# DSS_EDP0_V2A_CORE_VP_REGS_APB register map
Vendor: Texas Instruments
Registers are 32-bit, access not given, reset 0x0 unless marked. A register's access mark holds for its fields unless they carry their own. Offsets are as the file gives them; [hi:lo] are bit positions; {n}, {i} and the like mark numbered series.

## DSS_EDP0_V2A_CORE_VP_REGS_APB (part 2 of 4)
0x40 V2A__CORE_VP__REGS_APB_SW_CLK_H_p reset 0x64 — Core Clock frequency
  [7:0] SW_CLOCK_VAL_H rw — Clock frequency in decimal values. Should be loaded by API to the value that reflects the frequency of clock provided to core clock input.
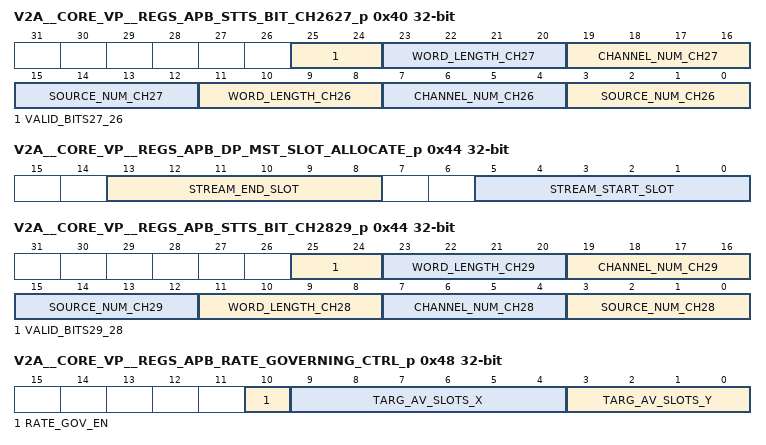
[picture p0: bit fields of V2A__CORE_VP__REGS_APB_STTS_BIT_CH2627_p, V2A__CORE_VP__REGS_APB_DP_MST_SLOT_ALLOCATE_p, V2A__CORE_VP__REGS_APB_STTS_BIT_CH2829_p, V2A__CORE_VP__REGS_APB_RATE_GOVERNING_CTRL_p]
0x40 V2A__CORE_VP__REGS_APB_STTS_BIT_CH2627_p — Channels 26,27 configuration
  [25:24] VALID_BITS27_26 rw — Valid Bits for channel 27 and 26 if force is enabled
  [23:20] WORD_LENGTH_CH27 rw — Channel 27 word length.
  [19:16] CHANNEL_NUM_CH27 rw — Channel 27 channel number.
  [15:12] SOURCE_NUM_CH27 rw — Channel 27 Source number.
  [11:8] WORD_LENGTH_CH26 rw — Channel 26 word length.
  [7:4] CHANNEL_NUM_CH26 rw — Channel 26 channel number.
  [3:0] SOURCE_NUM_CH26 rw — Channel 26 Source number.
0x44 V2A__CORE_VP__REGS_APB_SW_EVENTS0_p — Bits [7:0] of the software events status vector. This register is used to report internal events that have been detected by the firmware to the host processor. Register is written by the internal uCPU. It is cleared upon read by the Host processor. Reported events can be source of interrupt reported in APB_INT_STATUS[1] register if this interrupt is enabled. Detailed description of the currently supported events can be found in Cadence HD Display TX Controller Programming Interface document.
  [7:0] SW_EVENTS7_0 ro — Each bit represents a separate event reported by the internal uCPU. If bit is set to 1 event is reported. All events are cleared upon read. Detailed description in Cadence HD Display TX Controller Programming Interface document.
0x44 V2A__CORE_VP__REGS_APB_DP_MST_SLOT_ALLOCATE_p — Stream slots allocation in MST mode. This register defines slots in the MTP assigned to a given stream. All slots between start and and are assigned to the stream. Assignement of noncontiguous slots to a single stream is not supported.
  [13:8] STREAM_END_SLOT rw — Stream end slot. This value determines last slot in MTP assigned to a given stream. Allowed values are stream_start_slot-63.
  [5:0] STREAM_START_SLOT rw — Stream start slot. This value determines first slot in MTP assigned to a given stream. Allowed values are 1-63.
0x44 V2A__CORE_VP__REGS_APB_STTS_BIT_CH2829_p — Channels 28,29 configuration
  [25:24] VALID_BITS29_28 rw — Valid Bits for channel 29 and 28 if force is enabled
  [23:20] WORD_LENGTH_CH29 rw — Channel 29 word length.
  [19:16] CHANNEL_NUM_CH29 rw — Channel 29 channel number.
  [15:12] SOURCE_NUM_CH29 rw — Channel 29 Source number.
  [11:8] WORD_LENGTH_CH28 rw — Channel 28 word length.
  [7:4] CHANNEL_NUM_CH28 rw — Channel 28 channel number.
  [3:0] SOURCE_NUM_CH28 rw — Channel 28 Source number.
{0x44+4i} V2A__CORE_VP__REGS_APB_SW_EVENTS{i}_p (i=1..3) — SW Event {i} register
  [7:0] SW_EVENTS{8i+7}_{8i} ro — Each bit represents a separate event reported by the internal uCPU. If bit is set to 1 event is reported. All events are cleared upon read. Detailed description in Cadence HD Display TX Controller Programming Interface document.
0x48 V2A__CORE_VP__REGS_APB_RATE_GOVERNING_CTRL_p — Control rate governing for stream in MST mode.
  [10] RATE_GOV_EN rw — Enable rate governing. When set to 0, this stream will only output VCPF
  [9:4] TARG_AV_SLOTS_X rw — Target average number of slots per MTP configuration
  [3:0] TARG_AV_SLOTS_Y rw — Target average number of slots per MTP configuration. Fractional component
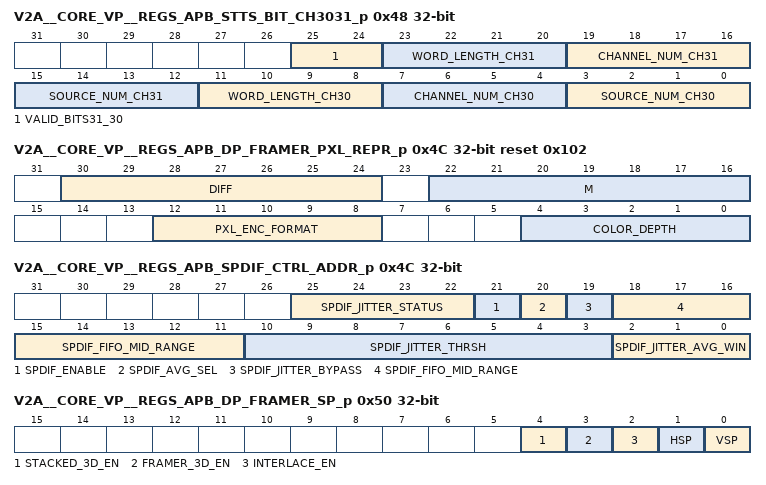
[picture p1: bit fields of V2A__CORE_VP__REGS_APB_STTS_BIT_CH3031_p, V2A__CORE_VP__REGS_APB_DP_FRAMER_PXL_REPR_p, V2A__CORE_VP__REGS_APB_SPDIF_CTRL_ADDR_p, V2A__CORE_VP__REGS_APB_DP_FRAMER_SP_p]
0x48 V2A__CORE_VP__REGS_APB_STTS_BIT_CH3031_p — Channels 30,31 configuration
  [25:24] VALID_BITS31_30 rw — Valid Bits for channel 31 and 30 if force is enabled
  [23:20] WORD_LENGTH_CH31 rw — Channel 31 word length.
  [19:16] CHANNEL_NUM_CH31 rw — Channel 31 channel number.
  [15:12] SOURCE_NUM_CH31 rw — Channel 31 Source number.
  [11:8] WORD_LENGTH_CH30 rw — Channel 30 word length.
  [7:4] CHANNEL_NUM_CH30 rw — Channel 30 channel number.
  [3:0] SOURCE_NUM_CH30 rw — Channel 30 Source number.
0x4C V2A__CORE_VP__REGS_APB_DP_FRAMER_PXL_REPR_p reset 0x102 — Video pixel format configuration. This register must be programmed prior enabling video and must not be changed while video is being transmitted.
  [30:24] DIFF rw — Difference between Denominator and Numerator of the ratio that describes valid symbols distribution. Example: If TU_VALID*=12.34 then DIFF=100-34=66. TU_VALID calculated according to DisplayPort specification. This setting apply only when compressed [DSC] stream is being transmitted.
  [22:16] M rw — Numerator of the ratio that describes valid symbols distribution. Example: If TU_VALID=12.34 then M=34. TU_VALID calculated according to DisplayPort specification. This setting apply only when compressed [DSC] stream is being transmitted.
  [12:8] PXL_ENC_FORMAT rw — Pixel encoding format: 1h - RGB 2h - YCbCr 4:4:4 4h - YCbCr 4:2:2 8h - Y CbCr 4:2:0 10h - Y-only All other values - RESERVED
  [4:0] COLOR_DEPTH rw — Color depth: 1h - 6 bpc, 2h - 8 bpc, 4h - 10 bpc, 8h - 12 bpc, 10h - 16 bpc, All other values - RESERVED
0x4C V2A__CORE_VP__REGS_APB_SPDIF_CTRL_ADDR_p — SPDIF control
  [25:22] SPDIF_JITTER_STATUS ro
  [21] SPDIF_ENABLE rw
  [20] SPDIF_AVG_SEL rw — SPDIF average Select
  [19] SPDIF_JITTER_BYPASS rw
  [18:11] SPDIF_FIFO_MID_RANGE rw
  [10:3] SPDIF_JITTER_THRSH rw — SPDIF Jitter threshold
  [2:0] SPDIF_JITTER_AVG_WIN rw — Spdif Jitter AVG Window
0x50 V2A__CORE_VP__REGS_APB_DP_FRAMER_SP_p — Synchronization signals polarity and 3D control. This register must be programmed prior enabling video and must not be changed while video is being transmitted.
  [4] STACKED_3D_EN rw — Unused. Kept RW for software backward compatibility.
  [3] FRAMER_3D_EN rw — 3D video enable, active high. This bit must be set when 3D Field Sequencial Stereo Format is enabled. Other 3D formats do not require setting this bit.
  [2] INTERLACE_EN rw — Interlaced video enable. Active high.
  [1] HSP rw — Video interface HSYNC polarity: 0 - active high, 1 - active low
  [0] VSP rw — Video interface VSYNC polarity: 0 - active high, 1 - active low
0x50 V2A__CORE_VP__REGS_APB_SPDIF_CH1_CS_3100_ADDR_p ro — SPDIF channel 1 status [31:00]
  [31:0] SPDIF_CH1_ST_STTS_BITS3100 — SPDIF Channel 1 Status bits[31:0]
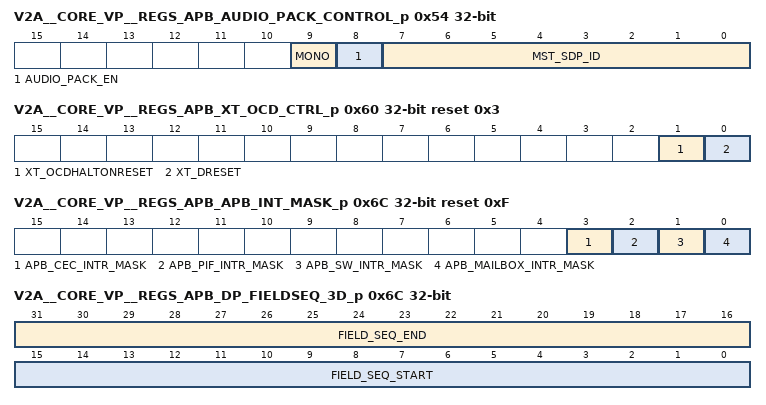
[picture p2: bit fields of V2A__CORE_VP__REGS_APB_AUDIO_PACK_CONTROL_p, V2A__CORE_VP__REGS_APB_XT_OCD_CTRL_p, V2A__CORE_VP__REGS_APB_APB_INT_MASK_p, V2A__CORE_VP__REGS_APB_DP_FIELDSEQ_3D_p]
0x54 V2A__CORE_VP__REGS_APB_AUDIO_PACK_CONTROL_p — Audio packet configuration.
  [9] MONO rw — In case of 2-channel layout and one lane configuration SW decides whether it is a stereo or mono transfer. Relevant for SDP HB3[2:0] - ChannelCount field
  [8] AUDIO_PACK_EN rw — Enables the Audio_Pack module, active high
  [7:0] MST_SDP_ID rw — Secondary-Data Packet ID. This field is transmitted in HB0 of the Audio SDP [Audio_TimeStamp and Audio_Stream].
0x54 V2A__CORE_VP__REGS_APB_SPDIF_CH1_CS_6332_ADDR_p ro — SPDIF channel 1 status [63:32]
  [31:0] SPDIF_CH1_ST_STTS_BITS6332 — SPDIF Channel 1 Status bits[63:32]
0x58 V2A__CORE_VP__REGS_APB_SPDIF_CH1_CS_9564_ADDR_p ro — SPDIF channel 1 status [95:64]
  [31:0] SPDIF_CH1_ST_STTS_BITS9564 — SPDIF Channel 1 Status bits[95:64]
0x5C V2A__CORE_VP__REGS_APB_SPDIF_CH1_CS_12796_ADDR_p ro — SPDIF channel 1 status [127:96]
  [31:0] SPDIF_CH1_ST_STTS_BITS12796 — SPDIF Channel 1 Status bits[127:96]
0x60 V2A__CORE_VP__REGS_APB_XT_OCD_CTRL_p reset 0x3 — Internal CPU - On Chip Debug (OCD) Ctrl Register
  [1] XT_OCDHALTONRESET rw — Internal CPU - Halt On Reget configuration register
  [0] XT_DRESET rw — Internal CPU - Dreset control register
0x60 V2A__CORE_VP__REGS_APB_SPDIF_CH1_CS_159128_ADDR_p ro — SPDIF channel 1 status [159:128]
  [31:0] SPDIF_CH1_ST_STTS_BITS159128 — SPDIF Channel 1 Status bits[159:128]
0x64 V2A__CORE_VP__REGS_APB_XT_OCD_CTRL_RO_p — Internal CPU - OCD R0 mode configuration
  [0] XT_XOCDMODE ro — Internal CPU - OCD mode configuration
0x64 V2A__CORE_VP__REGS_APB_LINE_THRESH_p reset 0x20 — Video FIFO latency threshold
  [5:0] CFG_ACTIVE_LINE_TRESH rw — Video Fifo Latency threshold. Defines the number of FIFO rows before reading starts. This setting depends on the transmitted video format and link rate.
0x64 V2A__CORE_VP__REGS_APB_SPDIF_CH1_CS_191160_ADDR_p ro — SPDIF channel 1 status [191:160]
  [31:0] SPDIF_CH1_ST_STTS_BITS191160 — SPDIF Channel 1 Status bits[191:160]
0x68 V2A__CORE_VP__REGS_APB_DP_VB_ID_p reset 0x9 — Vertical blanking ID
  [7:0] VB_ID rw — VB-ID as described in the DisplayPort specification. Bits that are timing dependent [VerticalBlanking_Flag, FieldID_Flag, HDCP SYNC DETECT, Compressed Stream_Flag] are overriden by hardware thus actual value written to the register is ignored.
0x68 V2A__CORE_VP__REGS_APB_SPDIF_CH2_CS_3100_ADDR_p ro — SPDIF channel 2 status [31:00]
  [31:0] SPDIF_CH2_ST_STTS_BITS3100 — SPDIF Channel 2 Status bits[31:0]
0x6C V2A__CORE_VP__REGS_APB_APB_INT_MASK_p reset 0xF — APB Interrupt Mask Register
  [3] APB_CEC_INTR_MASK rw — Reserved field. 0x0 when read. Writes ignored.
  [2] APB_PIF_INTR_MASK rw — PIF module Interrupt mask 0x0-interrupt enabled 0x1-interrupt disabled
  [1] APB_SW_INTR_MASK rw — SW Event Interrupt mask 0x0-interrupt enabled 0x1-interrupt disabled
  [0] APB_MAILBOX_INTR_MASK rw — Mailbox Interrupt mask 0x0-interrupt enabled 0x1-interrupt disabled
0x6C V2A__CORE_VP__REGS_APB_DP_FIELDSEQ_3D_p rw — Supporting configuration to switch from top/bottom on the input to field sequential on the output
  [31:16] FIELD_SEQ_END — Number of line in the frame where the Vblank part in the field sequential format ends
  [15:0] FIELD_SEQ_START — Number of line in the frame where the Vblank part in the field sequential format starts
0x6C V2A__CORE_VP__REGS_APB_SPDIF_CH2_CS_6332_ADDR_p ro — SPDIF channel 2 status [63:32]
  [31:0] SPDIF_CH2_ST_STTS_BITS6332 — SPDIF Channel 2 Status bits[63:32]
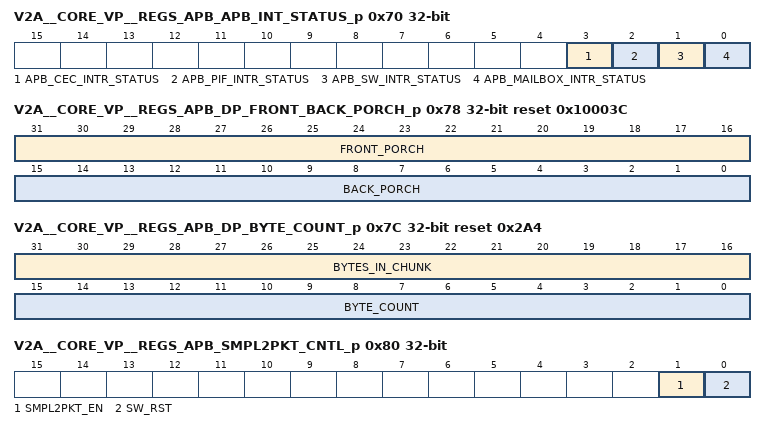
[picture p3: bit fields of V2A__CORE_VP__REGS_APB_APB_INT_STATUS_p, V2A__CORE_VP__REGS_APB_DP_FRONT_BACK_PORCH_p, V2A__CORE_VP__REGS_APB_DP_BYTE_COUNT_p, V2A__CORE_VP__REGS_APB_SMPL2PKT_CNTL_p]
0x70 V2A__CORE_VP__REGS_APB_APB_INT_STATUS_p — APB interrupt status register
  [3] APB_CEC_INTR_STATUS ro — Reserved.
  [2] APB_PIF_INTR_STATUS ro — PIF module Interrupt status. Active HIGH. If this bit is set further status should be read from SOURCE_PIF_INTERRUPT_SOURCE register. This bit is cleared automatically on read from SOURCE_PIF_INTERRUPT_SOURCE register.
  [1] APB_SW_INTR_STATUS ro — SW Events Interrupt status. Active HIGH. If this bit is set further status should be read from SW_EVENTSn registers. This bit is cleared automatically on read from SW_EVENTSn registers if there are no more events.
  [0] APB_MAILBOX_INTR_STATUS ro — Mailbox Interrupt status. Active HIGH. If this bit is set further status should be read from MAILBOX_INT_STATUS register. This bit is cleared automatically on read from MAILBOX_INT_STATUS register.
0x70 V2A__CORE_VP__REGS_APB_SPDIF_CH2_CS_9564_ADDR_p ro — SPDIF channel 2 status [95:64]
  [31:0] SPDIF_CH2_ST_STTS_BITS9564 — SPDIF Channel 2 Status bits[95:64]
0x74 V2A__CORE_VP__REGS_APB_SPDIF_CH2_CS_12796_ADDR_p ro — SPDIF channel 2 status [127:96]
  [31:0] SPDIF_CH2_ST_STTS_BITS12796 — SPDIF Channel 2 Status bits[127:96]
0x78 V2A__CORE_VP__REGS_APB_DP_FRONT_BACK_PORCH_p rw reset 0x10003C — Front and Back Porch configuration register. In case of compressed stream transmission (DSC) and split panel mode values in this register must be divided by 2 since VIF interface operates at pixel clock divided by 2. This will ensure the same timing compared to uncompressed stream and.
  [31:16] FRONT_PORCH — Value of the front porch
  [15:0] BACK_PORCH — Value of the back porch
0x78 V2A__CORE_VP__REGS_APB_SPDIF_CH2_CS_159128_ADDR_p ro — SPDIF channel 2 status [159:128]
  [31:0] SPDIF_CH2_ST_STTS_BITS159128 — SPDIF Channel 2 Status bits[159:128]
0x7C V2A__CORE_VP__REGS_APB_DP_BYTE_COUNT_p rw reset 0x2A4 — Number of bytes per lane/chunk parameters
  [31:16] BYTES_IN_CHUNK — Number of bytes in chunk per lane, including additional EOC symbol.
  [15:0] BYTE_COUNT — Total number of bytes in a line in case of non-DSC video. When DSC is enabled should be total number of bytes in a line *per lane*, including the additional EOC symbol[s].
0x7C V2A__CORE_VP__REGS_APB_SPDIF_CH2_CS_191160_ADDR_p ro — SPDIF channel 2 status [191:160]
  [31:0] SPDIF_CH2_ST_STTS_BITS191160 — SPDIF Channel 2 Status bits[191:160]
0x80 V2A__CORE_VP__REGS_APB_SMPL2PKT_CNTL_p — Sample 2 Packets Control Register
  [1] SMPL2PKT_EN rw — When high Sample to Packets Block starts.
  [0] SW_RST rw — Software reset. Active high.
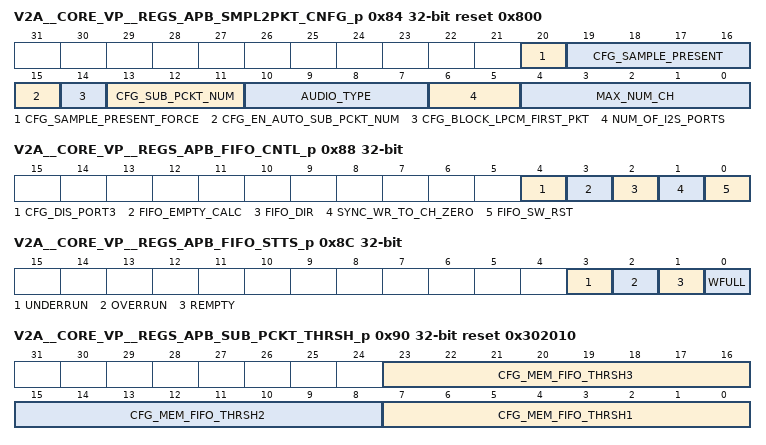
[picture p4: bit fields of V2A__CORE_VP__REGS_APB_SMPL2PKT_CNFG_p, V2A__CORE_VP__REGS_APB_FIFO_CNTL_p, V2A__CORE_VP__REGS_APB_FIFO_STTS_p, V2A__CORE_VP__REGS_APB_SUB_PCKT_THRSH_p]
0x84 V2A__CORE_VP__REGS_APB_SMPL2PKT_CNFG_p reset 0x800 — Sample 2 Packets Config Register
  [20] CFG_SAMPLE_PRESENT_FORCE rw — Force sample present bits
  [19:16] CFG_SAMPLE_PRESENT rw — Sample present bits if force them is active
  [15] CFG_EN_AUTO_SUB_PCKT_NUM rw — Enable automatics sub packet number. When enabled number of sub-packts will be set according to MEM FIFO number of samples.
  [14] CFG_BLOCK_LPCM_FIRST_PKT rw — 0 - All packets behave the same. 1- First lpcm audio packet is sent with 1 - SP.
  [13:11] CFG_SUB_PCKT_NUM rw — Number of sub-packets in HDMI audio 2-ch packet. 00: 1-SP 01: 2-SP 10: 3-SP 11: 4-SP. 100-111: NA.
  [10:7] AUDIO_TYPE rw — Audio Type setting. Packet is structured according to audio type.
  [6:5] NUM_OF_I2S_PORTS rw — Number ofactive I2S ports. 00- 1 port 01-2 ports 11- 4 ports 11 -NA.
  [4:0] MAX_NUM_CH rw — Number of channels to decode. 0: 1 channel 31: 32 channels
0x88 V2A__CORE_VP__REGS_APB_FIFO_CNTL_p — FIFO control register
  [4] CFG_DIS_PORT3 rw — 0 - Normal Operation. 1 - I2S port 3 is disabled [user should ignore its outputs]. This allows for 24-ch, 12-ch, 6-ch transfer.
  [3] FIFO_EMPTY_CALC rw — 0 - Empty is a function of read address. 1 - Empty is a function of BASE read address.
  [2] FIFO_DIR rw — 0 - smpl2pkt [inc_step=number of I2S ports] 1 - pkt2smpl [inc_step=num_ch_per_port]
  [1] SYNC_WR_TO_CH_ZERO rw — When high the last channel index synchronizes the write addresses [to the next channel group]
  [0] FIFO_SW_RST rw — Resets Fifo's write and read pointers. When FIFO configuration bits change this signal should be high [due to synchronization issues].
0x8C V2A__CORE_VP__REGS_APB_FIFO_STTS_p — FIFO Status register
  [3] UNDERRUN ro — Indicates a FIFO underrun error has occured - FIFO read when it was empty. For debug purposes, not synchronized.
  [2] OVERRUN ro — Indicates a FIFO overrun error has occured - FIFO written to when it was full. For debug purposes, not synchronized.
  [1] REMPTY ro — Indicates FIFO Empty. For debug purposes, not synchronized.
  [0] WFULL ro — Indicates FIFO Full. For debug purposes, not synchronized.
0x90 V2A__CORE_VP__REGS_APB_SUB_PCKT_THRSH_p reset 0x302010 — SUB Packet Threshold register
  [23:16] CFG_MEM_FIFO_THRSH3 rw — If number of samples in MEM FIFO is below Threshold 3: Each Packet will contain only 3 subpacket.
  [15:8] CFG_MEM_FIFO_THRSH2 rw — If number of samples in MEM FIFO is below Threshold2: Each Packet will contain only 2 subpacket.
  [7:0] CFG_MEM_FIFO_THRSH1 rw — If number of samples in MEM FIFO is below Threshold 1: Each Packet will contain only 1 subpacket.
0xA0 V2A__CORE_VP__REGS_APB_CDNS_DID_p ro reset 0x8546 — Number identifying the IP. Corresponds to Cadence IP Part Number.
  [31:0] IPVER — 0x8546 - DisplayPort 1.4/EmbeddedDisplayPort 1.4 Tx Combo Controller
0xA4 V2A__CORE_VP__REGS_APB_CDNS_RID0_p reset 0x2000 — Number identifying IP version.
  [15:0] IP_VERSION ro — IP version: r[15:4]v[3:0]
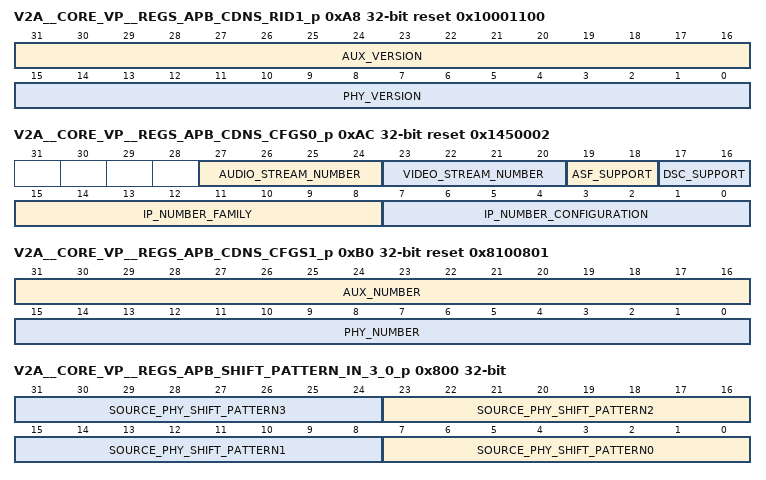
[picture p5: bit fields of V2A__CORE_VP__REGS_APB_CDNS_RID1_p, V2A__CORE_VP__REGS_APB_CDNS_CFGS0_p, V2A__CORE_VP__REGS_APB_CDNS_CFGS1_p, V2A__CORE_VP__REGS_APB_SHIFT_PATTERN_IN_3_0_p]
0xA8 V2A__CORE_VP__REGS_APB_CDNS_RID1_p ro reset 0x10001100 — Numbers identifying PHY and AUX version
  [31:16] AUX_VERSION — AUX version: r[31:20]v[19:16]
  [15:0] PHY_VERSION — PHY version: r[15:4]v[3:0]
0xAC V2A__CORE_VP__REGS_APB_CDNS_CFGS0_p reset 0x1450002 — Numbers identifying the capabilities/configuration of the MHDP controller. Values not explicitely listed below ar ereserved for future use.
  [27:24] AUDIO_STREAM_NUMBER ro — Secondary configuration. Number of audio streams supported
  [23:20] VIDEO_STREAM_NUMBER ro — Secondary configuration. Number of video streams supported
  [19:18] ASF_SUPPORT ro — Secondary configuration. ASF support. 0x0: ASF not supported, 0x1: ASF supported
  [17:16] DSC_SUPPORT ro — Secondary configuration. DSC support. 0x0: DSC not supported, 0x1: DSC supported
  [15:8] IP_NUMBER_FAMILY ro — Main configuration. IP Family Code. 0x00: Display TX Controller, 0x01: Display RX Controller
  [7:0] IP_NUMBER_CONFIGURATION ro — Main configuration. IP configuration. 0x00 - HDMI+DP+HDPC 0x01 - HDMI+HDCP 0x02 - DP+HDCP 0x03 - HDMI+DP
0xB0 V2A__CORE_VP__REGS_APB_CDNS_CFGS1_p ro reset 0x8100801 — Numbers identifying type of PHY and AUX are integrated in the IPS. Fixed for a given IPS configuration.
  [31:16] AUX_NUMBER — AUX IP Number, according to versioning scheme.
  [15:0] PHY_NUMBER — PHY IP Number, according to versioning scheme.
0x800 V2A__CORE_VP__REGS_APB_SHIFT_PATTERN_IN_3_0_p rw — HDMI shift pattern 3-0
  [8n+7:8n] SOURCE_PHY_SHIFT_PATTERN{n} (n=0..3) — Input to hdmi_pattern_shift
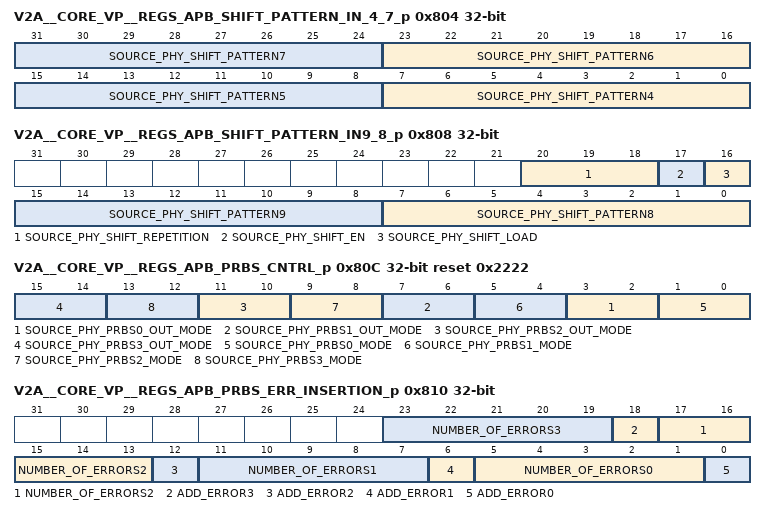
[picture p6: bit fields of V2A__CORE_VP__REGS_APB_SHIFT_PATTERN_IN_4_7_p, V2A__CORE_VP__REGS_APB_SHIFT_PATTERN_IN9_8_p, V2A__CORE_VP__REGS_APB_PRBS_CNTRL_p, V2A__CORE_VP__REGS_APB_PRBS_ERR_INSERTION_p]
0x804 V2A__CORE_VP__REGS_APB_SHIFT_PATTERN_IN_4_7_p rw — HDMI shift pattern 4-7
  [8n-25:8n-32] SOURCE_PHY_SHIFT_PATTERN{n} (n=4..7) — Input to hdmi_pattern_shift
0x808 V2A__CORE_VP__REGS_APB_SHIFT_PATTERN_IN9_8_p — HDMI shift pattern 9-8 with control bits
  [20:18] SOURCE_PHY_SHIFT_REPETITION rw — Shift repetition Number
  [17] SOURCE_PHY_SHIFT_EN rw — When 1 enable the Shift pattern Mechanism
  [16] SOURCE_PHY_SHIFT_LOAD rw — When 1 load the 80 bits of data
  [15:8] SOURCE_PHY_SHIFT_PATTERN9 rw — Input to hdmi_pattern_shift
  [7:0] SOURCE_PHY_SHIFT_PATTERN8 rw — Input to hdmi_pattern_shift
0x80C V2A__CORE_VP__REGS_APB_PRBS_CNTRL_p reset 0x2222 — PRBS control
  [4n+3:4n+2] SOURCE_PHY_PRBS{n}_OUT_MODE rw (n=0..3) — 00 = idle, output all zeros 01 = output 8 bits on pattern[7:0] 10 = output 1 bit on pattern[9] and output inverted bit on pattern[8] 11 = output 10 bits on pattern[9:0]
  [4n+1:4n] SOURCE_PHY_PRBS{n}_MODE rw (n=0..3) — 00 = PRBS11 01 = PRBS15 10 = PRBS7 11 = PRBS31
0x810 V2A__CORE_VP__REGS_APB_PRBS_ERR_INSERTION_p — PRBS error insertion
  [6n+5:6n+1] NUMBER_OF_ERRORS{n} rw (n=0..3) — The number of errors to be inserted when add_error is high.
  [18] ADD_ERROR3 rw — When high the PRBS generator inserts the number of errors written in number_of_errors field.
  [12] ADD_ERROR2 rw — When high the PRBS generator inserts the number of errors written in number_of_errors field.
  [6] ADD_ERROR1 rw — When high the PRBS generator inserts the number of errors written in number_of_errors field
  [0] ADD_ERROR0 rw — When high the PRBS generator inserts the number of errors written in number_of_errors field
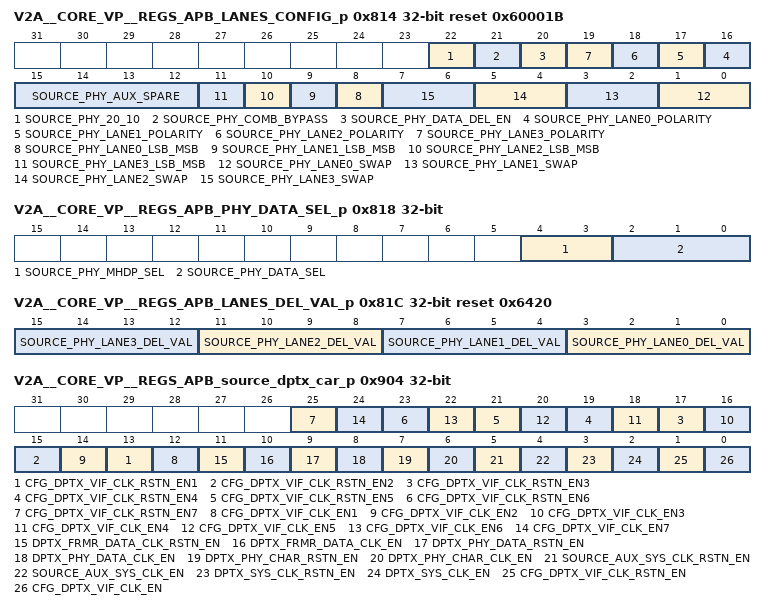
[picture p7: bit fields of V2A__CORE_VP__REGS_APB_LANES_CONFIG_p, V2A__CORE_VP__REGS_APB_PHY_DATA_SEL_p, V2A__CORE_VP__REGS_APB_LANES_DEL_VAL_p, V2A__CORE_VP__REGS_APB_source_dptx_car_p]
0x814 V2A__CORE_VP__REGS_APB_LANES_CONFIG_p reset 0x60001B — Lane control register: swap, order, polarity
  [22] SOURCE_PHY_20_10 rw — 1'b0: Data to PHY is 10 bit with char clock 1'd1: Data to PHY is 20 bit with data clock
  [21] SOURCE_PHY_COMB_BYPASS rw — Bypass swap invert and all combination
  [20] SOURCE_PHY_DATA_DEL_EN rw — enable configurable delay of lanes to be activated.if this bit is 0 the delay is only activated for DisplayPort mode with source_phy_data_sel=prbs or shift-mem
  [n+16] SOURCE_PHY_LANE{n}_POLARITY rw (n=0..3) — Reverse polarity of data, lane{n}
  [15:12] SOURCE_PHY_AUX_SPARE rw — Spare bits for aux **1.1**
  [n+8] SOURCE_PHY_LANE{n}_LSB_MSB rw (n=0..3) — Reverse order of data, lane{n}
  [2n+1:2n] SOURCE_PHY_LANE{n}_SWAP rw (n=0..3) — Swap control lane{n}
0x818 V2A__CORE_VP__REGS_APB_PHY_DATA_SEL_p — PHY data select DP/HDMI and HDMI data source
  [4:3] SOURCE_PHY_MHDP_SEL rw — 3'd0: tx_data = DP 3'd1: tx_data = HDMI 3'd2: tx_data = RSRV 3'd3: tx_data = RSRV
  [2:0] SOURCE_PHY_DATA_SEL rw — 3'd0: tx_data = phy_dout 3'd1: tx_data = phy_dout_bypass 3'd2: tx_data = source_phy_prbs_pout 3'd3: tx_data = source_phy_shift_pout
0x81C V2A__CORE_VP__REGS_APB_LANES_DEL_VAL_p reset 0x6420 — Lane delay control
  [4n+3:4n] SOURCE_PHY_LANE{n}_DEL_VAL rw (n=0..3) — delay for lane {n} this parameter can take values from 0 up to 8. All other values are reserved
0x904 V2A__CORE_VP__REGS_APB_source_dptx_car_p — DP TX clock and reset ctrl register
  [2n+11] CFG_DPTX_VIF_CLK_RSTN_EN{n} rw (n=1..7) — dptx_vif_clk_rstn enable for stream number {n} - active low
  [2n+10] CFG_DPTX_VIF_CLK_EN{n} rw (n=1..7) — dptx_vif_clk enable for stream number {n} - active high
  [11] DPTX_FRMR_DATA_CLK_RSTN_EN rw — dptx_frmr_data_clk_rstn enable - active low
  [10] DPTX_FRMR_DATA_CLK_EN rw — dptx_frmr_data_clk enable - active high
  [9] DPTX_PHY_DATA_RSTN_EN rw — dptx_phy_data_rstn enable - active low
  [8] DPTX_PHY_DATA_CLK_EN rw — dptx_phy_data_clk enable - active high
  [7] DPTX_PHY_CHAR_RSTN_EN rw — dptx_phy_char_rstn enable - active low
  [6] DPTX_PHY_CHAR_CLK_EN rw — dptx_phy_char_clk enable - active high
  [5] SOURCE_AUX_SYS_CLK_RSTN_EN rw — source_aux_sys_clk_rstn enable - active low
  [4] SOURCE_AUX_SYS_CLK_EN rw — source_aux_sys_clk enable - active high
  [3] DPTX_SYS_CLK_RSTN_EN rw — dptx_sys_clk_rstn enable - active low
  [2] DPTX_SYS_CLK_EN rw — dptx_sys_clk enable - active high
  [1] CFG_DPTX_VIF_CLK_RSTN_EN rw — dptx_vif_clk_rstn enable - active low
  [0] CFG_DPTX_VIF_CLK_EN rw — dptx_vif_clk enable - active high
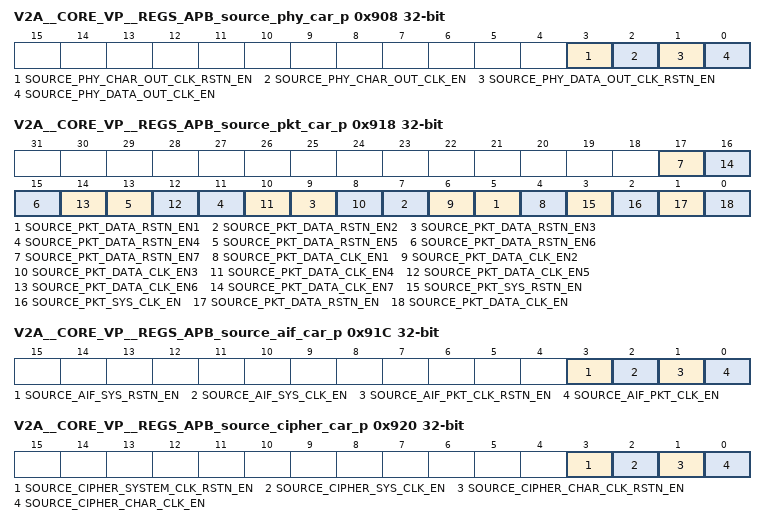
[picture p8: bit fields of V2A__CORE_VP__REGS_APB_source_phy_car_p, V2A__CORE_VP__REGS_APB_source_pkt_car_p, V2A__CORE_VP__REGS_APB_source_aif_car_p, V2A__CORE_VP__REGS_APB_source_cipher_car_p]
0x908 V2A__CORE_VP__REGS_APB_source_phy_car_p — Source PHY clock and reset ctrl register
  [3] SOURCE_PHY_CHAR_OUT_CLK_RSTN_EN rw — source_phy_char_out_clk_rstn enable - active low
  [2] SOURCE_PHY_CHAR_OUT_CLK_EN rw — source_phy_char_out_clk enable - active high
  [1] SOURCE_PHY_DATA_OUT_CLK_RSTN_EN rw — source_phy_data_out_clk_rstn enable - active low
  [0] SOURCE_PHY_DATA_OUT_CLK_EN rw — source_phy_data_out_clk enable - active high
0x918 V2A__CORE_VP__REGS_APB_source_pkt_car_p — PKT clock and reset ctrl register
  [2n+3] SOURCE_PKT_DATA_RSTN_EN{n} rw (n=1..7) — source_pkt_data_rstn_en{n} - active low
  [2n+2] SOURCE_PKT_DATA_CLK_EN{n} rw (n=1..7) — source_pkt_data_clk_en{n} - active high
  [3] SOURCE_PKT_SYS_RSTN_EN rw — source_pkt_sys_rstn_en - active low
  [2] SOURCE_PKT_SYS_CLK_EN rw — source_pkt_sys_clk_en - active high
  [1] SOURCE_PKT_DATA_RSTN_EN rw — source_pkt_data_rstn_en - active low
  [0] SOURCE_PKT_DATA_CLK_EN rw — source_pkt_data_clk_en - active high
0x91C V2A__CORE_VP__REGS_APB_source_aif_car_p — AIF clock and reset ctrl register
  [3] SOURCE_AIF_SYS_RSTN_EN rw — source_aif_sys_rstn enable - active low
  [2] SOURCE_AIF_SYS_CLK_EN rw — source_aif_sys_clk enable - active high
  [1] SOURCE_AIF_PKT_CLK_RSTN_EN rw — source_aif_pkt_clk_rstn enable - active low
  [0] SOURCE_AIF_PKT_CLK_EN rw — source_aif_pkt_clk enable - active high
0x920 V2A__CORE_VP__REGS_APB_source_cipher_car_p — Cipher clock and reset ctrl register
  [3] SOURCE_CIPHER_SYSTEM_CLK_RSTN_EN rw — source_cipher_system_clk_rstn enable - active low [Only when HDCP used]
  [2] SOURCE_CIPHER_SYS_CLK_EN rw — source_cipher_sys_clk enable - active high [Only when HDCP used]
  [1] SOURCE_CIPHER_CHAR_CLK_RSTN_EN rw — source_cipher_char_clk_rstn enable - active low [Only when HDCP used]
  [0] SOURCE_CIPHER_CHAR_CLK_EN rw — source_cipher_char_clk enable - active high [Only when HDCP used]
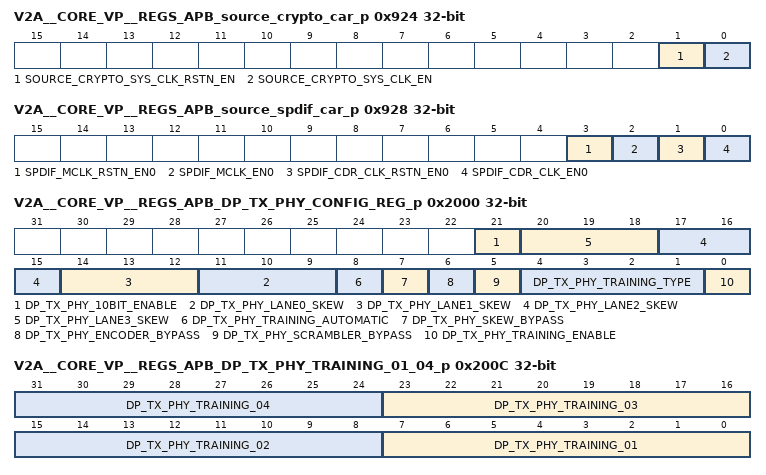
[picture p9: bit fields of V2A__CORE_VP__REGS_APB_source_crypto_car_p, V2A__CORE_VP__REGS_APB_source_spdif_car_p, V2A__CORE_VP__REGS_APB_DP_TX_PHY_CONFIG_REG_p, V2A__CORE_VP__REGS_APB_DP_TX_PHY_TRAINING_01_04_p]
0x924 V2A__CORE_VP__REGS_APB_source_crypto_car_p — Crypto clock and reset ctrl register
  [1] SOURCE_CRYPTO_SYS_CLK_RSTN_EN rw — source_crypto_sys_clk_rstn enable - active low [Only when HDCP used]
  [0] SOURCE_CRYPTO_SYS_CLK_EN rw — source_crypto_sys_clk enable - active high [Only when HDCP used]
0x928 V2A__CORE_VP__REGS_APB_source_spdif_car_p — SPDIF clock and reset ctrl register
  [3] SPDIF_MCLK_RSTN_EN0 rw — spdif_mclk_rstn enable0 - active low
  [2] SPDIF_MCLK_EN0 rw — spdif_mclk enable0 - active high
  [1] SPDIF_CDR_CLK_RSTN_EN0 rw — spdif_cdr_clk_rstn enable0 - active low
  [0] SPDIF_CDR_CLK_EN0 rw — spdif_cdr_clk enable0 - active high
0x2000 V2A__CORE_VP__REGS_APB_DP_TX_PHY_CONFIG_REG_p — DPTX PHY control
  [21] DP_TX_PHY_10BIT_ENABLE rw — Used to enable the 10-bit mode. Active high.
  [3n+11:3n+9] DP_TX_PHY_LANE{n}_SKEW rw (n=0..3) — Specifies the programmable lane{n} skew.
  [8] DP_TX_PHY_TRAINING_AUTOMATIC rw — When set, the dp_tx_phy_scrambler_bypass and the dp_tx_phy_encoder_bypass bits are ignored during training pattern generation. This is a debug feature.
  [7] DP_TX_PHY_SKEW_BYPASS rw — Used to bypass the lane skew. Active high. This is a debug feature.
  [6] DP_TX_PHY_ENCODER_BYPASS rw — Used to bypass the encoder. Active high. This is a debug feature.
  [5] DP_TX_PHY_SCRAMBLER_BYPASS rw — Used to bypass the scrambler. Active high. This is a debug feature.
  [4:1] DP_TX_PHY_TRAINING_TYPE rw — Specifies the training pattern type used as follows: 0000 PRBS7 0001 TPS1 0010 TPS2 0011 TPS3 0100 TPS4 0101 custom 80-bit pattern 0110 D10.2 training pattern 0111 Symbol Error Rate Measurement pattern 1000 CP2520 pattern1 1001 CP2520 pattern2 1010 CP2520 pattern3 others reserved
  [0] DP_TX_PHY_TRAINING_ENABLE rw — Enables the training sequence [when set to 1].
0x2004 V2A__CORE_VP__REGS_APB_DP_TX_PHY_SW_RESET_p — DPTC PHY software reset
  [0] DP_TX_PHY_SW_RST rw — Software reset. Active high.
0x2008 V2A__CORE_VP__REGS_APB_DP_TX_PHY_SCRAMBLER_SEED_p reset 0xFFFF — Scrambler seed
  [15:0] DP_TX_PHY_SCRAMBLER_SEED rw — Scrambler seed range 0-0xFFFF
0x200C V2A__CORE_VP__REGS_APB_DP_TX_PHY_TRAINING_01_04_p rw — Custom training value bytes 1-4
  [8n-1:8n-8] DP_TX_PHY_TRAINING_{n:02} (n=1..4) — Byte {n} of the 80-bit custom training data.
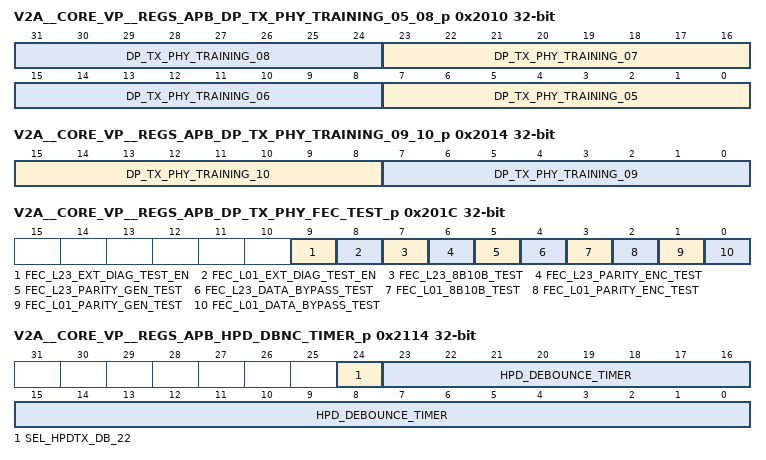
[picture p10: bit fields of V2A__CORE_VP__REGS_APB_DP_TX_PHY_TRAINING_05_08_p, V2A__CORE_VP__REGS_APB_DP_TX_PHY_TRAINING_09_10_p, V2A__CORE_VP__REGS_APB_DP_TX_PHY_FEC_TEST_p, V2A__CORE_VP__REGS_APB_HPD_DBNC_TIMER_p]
0x2010 V2A__CORE_VP__REGS_APB_DP_TX_PHY_TRAINING_05_08_p rw — Custom training value bytes 5-8
  [8n-33:8n-40] DP_TX_PHY_TRAINING_{n:02} (n=5..8) — Byte {n} of the 80-bit custom training data.
0x2014 V2A__CORE_VP__REGS_APB_DP_TX_PHY_TRAINING_09_10_p — Custom training value bytes 9-10
  [15:8] DP_TX_PHY_TRAINING_10 rw — Byte 10 of the 80-bit custom training data.
  [7:0] DP_TX_PHY_TRAINING_09 rw — Byte 9 of the 80-bit custom training data.
0x2018 V2A__CORE_VP__REGS_APB_DP_TX_PHY_SR_INTERVAL_p reset 0xFC — Custom CP2520 SR interval
  [15:0] DP_TX_PHY_SR_INTERVAL rw — CP2520 test pattern SR Interval definition
0x201C V2A__CORE_VP__REGS_APB_DP_TX_PHY_FEC_TEST_p — FEC IP test register. Used for fault injection into the FEC IP to test diagnostic mechanisms.
  [9] FEC_L23_EXT_DIAG_TEST_EN rw — Encoder 1 external diagnostic test enable. When asserted, a corruption is injected in the external diagnostic reference module which generate an external diagnostic support module fault. To perform external diagnostic test this bit must be set first and then one of the bits 7-4 must be set. Both must be a separate writes. NOTE: This bit cannot be set when bypess, encoder, decoder or 8b10b tests are performed.
  [8] FEC_L01_EXT_DIAG_TEST_EN rw — Encoder 0 external diagnostic test enable. When asserted, a corruption is injected in the external diagnostic reference module which generate an external diagnostic support module fault. To perform external diagnostic test this bit must be set first and then one of the bits 3-0 must be set. Both must be a separate writes. NOTE: This bit cannot be set when bypess, encoder, decoder or 8b10b tests are performed.
  [7] FEC_L23_8B10B_TEST rw — When asserted, a corruption is injected at the interface of the internal diagnostic module which generate a fault in the 8b10b check of the FEC IP datapath for lanes 2 and 3. Bit is self cleared.
  [6] FEC_L23_PARITY_ENC_TEST rw — When asserted, a corruption is injected at the interface of the internal diagnostic module which generate a fault in the parity enc check of the FEC IP datapath for lanes 2 and 3. Bit is self cleared.
  [5] FEC_L23_PARITY_GEN_TEST rw — When asserted, a corruption is injected at the interface of the internal diagnostic module which generate a fault in the parity gen check of the FEC IP datapaths for lanes 2 and 3. Bit is self cleared.
  [4] FEC_L23_DATA_BYPASS_TEST rw — When asserted, a corruption is injected at the interface of the internal diagnostic module which generate a fault in the bypass check for of the FEC IP datapathe for lanes 2 and 3. Bit is self cleared.
  [3] FEC_L01_8B10B_TEST rw — When asserted, a corruption is injected at the interface of the internal diagnostic module which generate a fault in the 8b10b check of the FEC IP datapath for lanes 0 and 1. Bit is self cleared.
  [2] FEC_L01_PARITY_ENC_TEST rw — When asserted, a corruption is injected at the interface of the internal diagnostic module which generate a fault in the parity enc check of the FEC IP datapath for lanes 0 and 1. Bit is self cleared.
  [1] FEC_L01_PARITY_GEN_TEST rw — When asserted, a corruption is injected at the interface of the internal diagnostic module which generate a fault in the parity gen check of the FEC IP datapath for lanes 0 and 1. Bit is self cleared.
  [0] FEC_L01_DATA_BYPASS_TEST rw — When asserted, a corruption is injected at the interface of the internal diagnostic module which generate a fault in the bypass check for of the FEC IP datapath for lanes 0 and 1. Bit is self cleared.
0x2100 V2A__CORE_VP__REGS_APB_HPD_IRQ_DET_MIN_TIMER_p reset 0xC350 — HPD min timer for irq, define the minimum pclk cycles that the HPD pulse will be considered as IRQ
  [23:0] HPD_IRQ_DET_MIN_TIMER rw — HPD min timer for interrupt.
0x2104 V2A__CORE_VP__REGS_APB_HPD_IRQ_DET_MAX_TIMER_p reset 0x186A0 — HPD max timer for irq, define the maximum pclk cycles that the HPD pulse will be considered as IRQ
  [23:0] HPD_IRQ_DET_MAX_TIMER rw — HPD max timer
0x2108 V2A__CORE_VP__REGS_APB_HPD_UNPLGED_DET_MIN_TIMER_p reset 0x30D40 — HPD min timer for HPD detect, define the minimum pclk cycles that the HPD is low
  [23:0] HPD_UNPLGED_DET_MIN_TIMER rw — HPD unplugged timer
0x210C V2A__CORE_VP__REGS_APB_HPD_STABLE_TIMER_p reset 0x186A0 — Timer for detecting HPD stable, count in system clock cycles.
  [23:0] HPD_STABLE_TIMER rw — HPD stable timer counter setup.
0x2110 V2A__CORE_VP__REGS_APB_HPD_FILTER_TIMER_p reset 0x7A12 — Timer for filtering small pulses on HPD input.
  [23:0] HPD_FILTER_TIMER rw — HPD glitch filter counter setup.
0x2114 V2A__CORE_VP__REGS_APB_HPD_DBNC_TIMER_p — HPD debouncer control
  [24] SEL_HPDTX_DB_22 rw — Debouncer enable 0 - debouncer disabled 1 - debouncer enabled
  [23:0] HPD_DEBOUNCE_TIMER rw — HPD debounce timer setup.
0x211C V2A__CORE_VP__REGS_APB_HPD_EVENT_MASK_p — Mask of HPD interrupt and status
  [3:0] HPD_EVENTS_MASK rw — HPD mask events
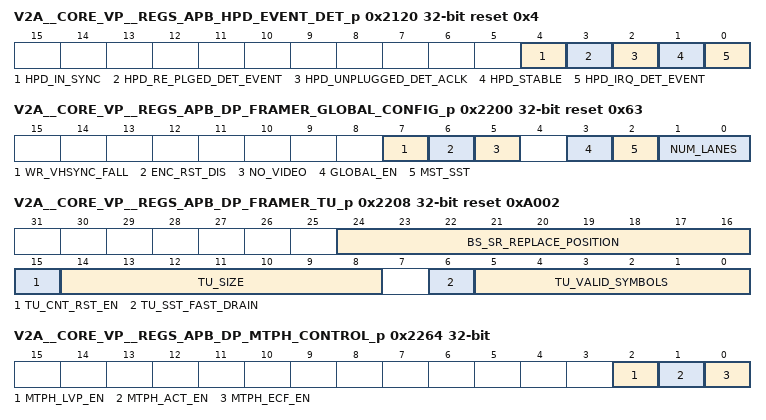
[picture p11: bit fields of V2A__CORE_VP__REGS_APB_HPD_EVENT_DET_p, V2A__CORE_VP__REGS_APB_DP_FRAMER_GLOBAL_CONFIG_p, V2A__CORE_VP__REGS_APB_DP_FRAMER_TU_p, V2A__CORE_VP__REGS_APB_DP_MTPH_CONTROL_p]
0x2120 V2A__CORE_VP__REGS_APB_HPD_EVENT_DET_p reset 0x4 — HPD interrupt and status
  [4] HPD_IN_SYNC ro — HDP in sync detected
  [3] HPD_RE_PLGED_DET_EVENT ro — HPD Re-Plugged event detected.
  [2] HPD_UNPLUGGED_DET_ACLK ro — HPD Un-Plugged event detected.
  [1] HPD_STABLE ro — HPD Stable indication
  [0] HPD_IRQ_DET_EVENT ro — Bit 0 - HPD irq event
0x2200 V2A__CORE_VP__REGS_APB_DP_FRAMER_GLOBAL_CONFIG_p reset 0x63 — Global configuration of the framer module.
  [7] WR_VHSYNC_FALL rw — When set to 1 change the write state machine to sync on falling edge of vsync. Used only for debug purpose.
  [6] ENC_RST_DIS rw — Unused. Kept RW for software backward compatibility.
  [5] NO_VIDEO rw — No-video mode configuration bit. Relevant only in SST mode. When this bit is set high and framer is enabled then IP operates in no-video mode i.e. BS symbol is generated every 8192 link symbols. In this mode audio data can be transmitted.
  [3] GLOBAL_EN rw — Global enable for complete Framer module, active high. It is deasserted during configuration phase. Once configuration is finished, it is asserted.
  [2] MST_SST rw — Mode select: 0 - SST mode 1 - MST mode Static cofiguration bit that must be set before link training.
  [1:0] NUM_LANES rw — Number of lanes: 0h - One lane [Lane 0 only] 1h - Two lanes [Lanes 0 and 1 only] 2h - Reserved 3h - Four lanes [Lanes 0, 1, 2, and 3]. This value can only be changed before link training and further it can by modified during link training in case link training for a given lane configuration fails. This field must not be changed after link training.
0x2204 V2A__CORE_VP__REGS_APB_DP_SW_RESET_p — Unused. Bit [0] kept RW for software backward compatibility.
  [0] SW_RST rw — Unused. Kept RW for software backward compatibility.
0x2208 V2A__CORE_VP__REGS_APB_DP_FRAMER_TU_p reset 0xA002 — Transfer Unit configuration register. Relevant only in SST mode. These register must be set before transitioning to video mode.
  [24:16] BS_SR_REPLACE_POSITION rw — Static debug register. When set to non-zero value, the BS counter will be reinitialized to this value that will result in earlier initial SR insertion.
  [15] TU_CNT_RST_EN rw — Unused. Kept RW for software backward compatibility.
  [14:8] TU_SIZE rw — Transfer Unit size. Even values between 32 and 64 are supported.
  [6] TU_SST_FAST_DRAIN rw — Allow the video FIFO to drain faster at end of line. This setting applies only to SST mode.
  [5:0] TU_VALID_SYMBOLS rw — Number of valid symbols per Transfer Unit [TU]. Rounded down to lower integer value [refer to equation in DP specification]. Allowed values are 1 to [TU_size-1]. TU valid smaller than one that would result this register to be set to 0 are not supported by the IP. This setting applies only to SST mode.
0x2218 V2A__CORE_VP__REGS_APB_DP_FRAMER_BS_SR_INTRVL_p reset 0x200 — SR insertion interval for SST mode.
  [9:0] BS_SR_INTERVAL rw — Static debug register. Controls how often BS is replaced by SR in SST mode. Default value of 512 results in every 512th BS being replaced by SR as per DP spec. This register can only be changed for a test purposes in order to speed up BS-SR replacement.
0x2258 V2A__CORE_VP__REGS_APB_DP_MTPH_ECF_SLOTS_31_0_p rw — Bits [31:1] contains which MST timeslot 31-1 should be encrypted. Bit [0] must be set to 1 to enable encryption. Relevant only in MST mode.
  [31:0] TSLOT_ENCRYPT31_0
0x225C V2A__CORE_VP__REGS_APB_DP_MTPH_ECF_SLOTS_63_32_p rw — Contains which MST timeslot 63-32 should be encrypted. This register must be set properly before ECF sequence is triggered. Relevant only in MST mode.
  [31:0] TSLOT_ENCRYPT63_32
0x2260 V2A__CORE_VP__REGS_APB_DP_MTPH_LVP_SYMBOL_p reset 0x531F — Link Verification Pattern value to be inserted in the MTP header. Relevant only in MST mode.
  [15:0] MTPH_LVP_SYM rw — Symbol value for LINK VERIFICATION PATTERN [LVP]
0x2264 V2A__CORE_VP__REGS_APB_DP_MTPH_CONTROL_p — MTP header control. Relevant only in MST mode.
  [2] MTPH_LVP_EN rw — Unused. Kept RW for software backward compatibility.
  [1] MTPH_ACT_EN wo — MST feature when written with value 1, an ACT sequence will be triggered for slot allocation control. This bit is write only.
  [0] MTPH_ECF_EN rw — Unused. Kept RW for software backward compatibility.
